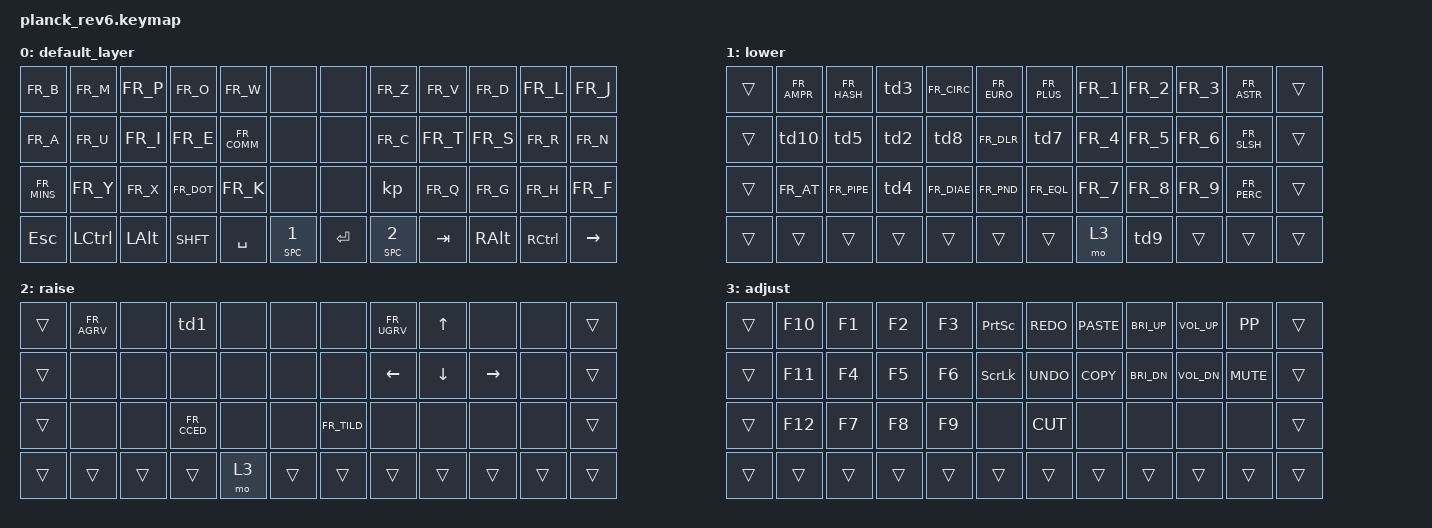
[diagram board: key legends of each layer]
/*
 * Copyright (c) 2020 The ZMK Contributors
 *
 * SPDX-License-Identifier: MIT
 */

#include "keys_fr.h"
#include <behaviors.dtsi>
#include <dt-bindings/zmk/keys.h>

/ {
    conditional_layers {
        compatible = "zmk,conditional-layers";

        tri_layer {
            if-layers = <4 6>;
            then-layer = <7>;
        };
    };

    combos {
        compatible = "zmk,combos";

        // symbols

        cb_excl {               // !
            bindings = <&kp EXCL>;
            key-positions = <1 13>;
            timeout-ms = <30>;
        };

        cb_at {               // @
            bindings = <&kp AT>;
            key-positions = <2 14>;
            timeout-ms = <30>;
        };

        cb_hash {               // #
            bindings = <&kp HASH>;
            key-positions = <3 15>;
            timeout-ms = <30>;
        };

        cb_dllr {               // $
            bindings = <&kp DLLR>;
            key-positions = <4 16>;
            timeout-ms = <30>;
        };

        cb_prcnt {              // %
            bindings = <&kp PRCNT>;
            key-positions = <5 17>;
            timeout-ms = <30>;
        };

        cb_caret {             // ^
            bindings = <&kp CARET>;
            key-positions = <6 18>;
            timeout-ms = <30>;
        };

        cb_amps {               // &
            bindings = <&kp AMPS>;
            key-positions = <7 19>;
            timeout-ms = <30>;
        };

        cb_mult {             // *
            bindings = <&kp ASTERISK>;
            key-positions = <8 20>;
            timeout-ms = <30>;
        };

        cb_lparen {
            bindings = <&kp LEFT_PARENTHESIS>;
            key-positions = <9 21>;
            timeout-ms = <30>;
        };

        cb_rparen {
            bindings = <&kp RIGHT_PARENTHESIS>;
            key-positions = <10 22>;
            timeout-ms = <30>;
        };
    };

    behaviors {
                lt_qk: layer_toggle_quick {
            compatible = "zmk,behavior-hold-tap";
            label = "LAYER_TOGGLE_QUICK";
            #binding-cells = <2>;
            flavor = "tap-preferred";
            tapping-term-ms = <150>;
            quick-tap-ms = <QUICK_TAP_MS>;
            bindings = <&mo>, <&kp>;
        };

        mt_sk: mod_tap_sticky {
            compatible = "zmk,behavior-hold-tap";
            label = "MOD_TAP_STICKY";
            #binding-cells = <2>;
            flavor = "tap-preferred";
            tapping-term-ms = <150>;
            quick-tap-ms = <200>;
            bindings = <&sk>, <&kp>;
        };

        ht: hold_tap {
            compatible = "zmk,behavior-hold-tap";
            label = "HOLD_TAP";
            #binding-cells = <2>;
            tapping_term_ms = <200>;
            quick_tap_ms = <200>;
            flavor = "tap-preferred";
            bindings = <&kp>, <&kp>;
        };

        lswp: left_swp {
            label = "LSWAP";
            compatible = "zmk,behavior-tap-dance";
            #binding-cells = <0>;
            tapping-term-ms = <200>;
            bindings = <&sk LGUI>, <&mo 0>, <&tog 0>;
        };

        rswp: right_swap {
            compatible = "zmk,behavior-tap-dance";
            label = "RIGHT_SWAP";
            #binding-cells = <0>;
            tapping-term-ms = <200>;   
            bindings = <&sk RGUI>, <&mo 0>, <&tog 0>;     
        };

        interrogation: interrogation {
            compatible = "zmk,behavior-mod-morph";
            label = "INTERROGATION";
            bindings = <&kp MINUS>, <&kp QUESTION>;

            #binding-cells = <0>;
            mods = <(MOD_LSFT|MOD_RSFT)>;
        };

        virgule: virgule {
            compatible = "zmk,behavior-mod-morph";
            label = "VIRGULE";
            bindings = <&kp COMMA>, <&kp SEMI>;

            #binding-cells = <0>;
            mods = <(MOD_LSFT|MOD_RSFT)>;
        };

        point: point {
            compatible = "zmk,behavior-mod-morph";
            label = "POINT";
            bindings = <&kp PERIOD>, <&kp COLON>;

            #binding-cells = <0>;
            mods = <(MOD_LSFT|MOD_RSFT)>;
        };

        zoom: zoom {
            compatible = "zmk,behavior-mod-morph";
            label = "ZOOM";
            bindings = <&kp LC(PLUS)>, <&kp LC(MINUS)>;

            #binding-cells = <0>;
            mods = <(MOD_LSFT|MOD_RSFT)>;        
        };

        circonflexe: circonflexe {
            compatible = "zmk,behavior-mod-morph";
            label = "CIRCONFLEXE";
            bindings = <&kp CARET>, <&kp RA(NUMBER_6)>;

            #binding-cells = <0>;
            mods = <(MOD_LSFT|MOD_RSFT)>;
        };

        inferieur: inferieur {
            compatible = "zmk,behavior-mod-morph";
            label = "INFERIEUR";
            bindings = <&kp LT>, <&none>;

            #binding-cells = <0>;
            mods = <(MOD_LSFT|MOD_RSFT)>;
        };

        superieur: superieur {
            compatible = "zmk,behavior-mod-morph";
            label = "SUPERIEUR";
            bindings = <&kp GREATER_THAN>, <&none>;

            #binding-cells = <0>;
            mods = <(MOD_LSFT|MOD_RSFT)>;
        };

        monnaies: monnaies {
            compatible = "zmk,behavior-mod-morph";
            label = "MONNAIES";
            bindings = <&kp DOLLAR>, <&sl 8>;

            #binding-cells = <0>;
            mods = <(MOD_LSFT|MOD_RSFT)>;
        };

        pourcent: pourcent {
            compatible = "zmk,behavior-mod-morph";
            label = "POURCENT";
            bindings = <&kp PERCENT>, <&none>;

            #binding-cells = <0>;
            mods = <(MOD_LSFT|MOD_RSFT)>;
        };

        anti_circonflexe: anti_circonflexe {
            compatible = "zmk,behavior-mod-morph";
            label = "ANTI_CIRCONFLEXE";
            bindings = <&kp LEFT_BRACE>, <&none>;
            #binding-cells = <0>;
            mods = <(MOD_LSFT|MOD_RSFT)>;
        };

        point_mort: point_mort {
            compatible = "zmk,behavior-mod-morph";
            label = "POINT_MORT";
            bindings = <&kp RIGHT_BRACE>, <&kp RA(N7)>;
            #binding-cells = <0>;
            mods = <(MOD_LSFT|MOD_RSFT)>;
        };

        egal: egal {
            compatible = "zmk,behavior-mod-morph";
            label = "EGAL";
            bindings = <&kp EQUAL>, <&none>;

            #binding-cells = <0>;
            mods = <(MOD_LSFT|MOD_RSFT)>;
        };

        tilde: tilde {
            compatible = "zmk,behavior-mod-morph";
            label = "TILDE";
            bindings = <&kp TILDE>, <&kp RA(TILDE)>;

            #binding-cells = <0>;
            mods = <(MOD_LSFT|MOD_RSFT)>;
        };

        onedk: onedk {
            compatible = "zmk,behavior-mod-morph";
            label = "ONEDK";
            bindings = <&sl 1>, <&kp EXCL>;

            #binding-cells = <0>;
            mods = <(MOD_LSFT|MOD_RSFT)>;
        };

        barre: barre {
            compatible = "zmk,behavior-mod-morph";
            label = "BARRE";
            bindings = <&kp MINUS>, <&kp RA(LS(N7))>;
            #binding-cells = <0>;
            mods = <(MOD_LSFT|MOD_RSFT)>;
        };

        grave: grave {
            compatible = "zmk,behavior-mod-morph";
            label = "GRAVE";
            bindings = <&kp GRAVE>, <&kp RA(GRAVE)>;

            #binding-cells = <0>;
            mods = <(MOD_LSFT|MOD_RSFT)>;
        };

        aigu: aigu {
            compatible = "zmk,behavior-mod-morph";
            label = "AIGU";
            bindings = <&kp SQT>, <&kp RA(SINGLE_QUOTE)>;

            #binding-cells = <0>;
            mods = <(MOD_LSFT|MOD_RSFT)>;
        };

        fois: fois {
            compatible = "zmk,behavior-mod-morph";
            label = "FOIS";
            bindings = <&kp ASTERISK>, <&kp RA(EQUAL)>;

            #binding-cells = <0>;
            mods = <(MOD_LSFT|MOD_RSFT)>;
        };


        division: division {
            compatible = "zmk,behavior-mod-morph";
            label = "DIVISION";
            bindings = <&kp SLASH>, <&kp RA(LS(EQUAL))>;

            #binding-cells = <0>;
            mods = <(MOD_LSFT|MOD_RSFT)>;
        };

        rond_mort: rond_mort {
            compatible = "zmk,behavior-mod-morph";
            label = "ROND_MORT";
            bindings = <&kp AT>, <&kp RA(N7)>;

            #binding-cells = <0>;
            mods = <(MOD_LSFT|MOD_RSFT)>;
        };

        barre_verticale: barre_verticale {
            compatible = "zmk,behavior-mod-morph";
            label = "BARRE_VERTICALE";
            bindings = <&kp LS(BACKSLASH)>, <&kp RA(LS(BACKSLASH))>;

            #binding-cells = <0>;
            mods = <(MOD_LSFT|MOD_RSFT)>;
        };

        truc: truc {
            compatible = "zmk,behavior-mod-morph";
            label = "TRUC";
            bindings = <&kp EXCLAMATION>, <&kp RA(BACKSLASH)>;

            #binding-cells = <0>;
            mods = <(MOD_LSFT|MOD_RSFT)>;
        };

        plus: plus {
            compatible = "zmk,behavior-mod-morph";
            label = "PLUS";
            bindings = <&kp PLUS>, <&none>;

            #binding-cells = <0>;
            mods = <(MOD_LSFT|MOD_RSFT)>;
        };

        backslash: backslash {
            compatible = "zmk,behavior-mod-morph";
            label = "BACKSLASH";
            bindings = <&kp BACKSLASH>, <&sl 5>;

            #binding-cells = <0>;
            mods = <(MOD_LSFT|MOD_RSFT)>;
        };
    };

    macros {
        e_circonflexe_min: e_circonflexe_min {
            compatible = "zmk,behavior-macro";
            #binding-cells = <0>;
            bindings =
                <&macro_press>,
                <&kp RALT>,
                <&macro_tap>,
                <&kp NUMBER_6>,
                <&macro_release>,
                <&kp RALT>,
                <&macro_tap>,
                <&kp E>;

            label = "E_CIRCONFLEXE_MIN";
        };

        e_circonflexe_maj: e_circonflexe_maj {
            compatible = "zmk,behavior-macro";
            #binding-cells = <0>;
            bindings =
                <&macro_press>,
                <&kp RALT>,
                <&macro_tap>,
                <&kp NUMBER_6>,
                <&macro_release>,
                <&kp RALT>,
                <&macro_tap>,
                <&kp LS(E)>;

            label = "E_CIRCONFLEXE_MAJ";
        };

        u_circonflexe_maj: u_circonflexe_maj {
            compatible = "zmk,behavior-macro";
            #binding-cells = <0>;
            bindings =
                <&macro_press>,
                <&kp RALT>,
                <&macro_tap>,
                <&kp NUMBER_6>,
                <&macro_release>,
                <&kp RALT>,
                <&macro_tap>,
                <&kp LS(U)>;

            label = "U_CIRCONFLEXE_MAJ";
        };

        u_circonflexe_min: u_circonflexe_min {
            compatible = "zmk,behavior-macro";
            #binding-cells = <0>;
            bindings =
                <&macro_press>,
                <&kp RALT>,
                <&macro_tap>,
                <&kp NUMBER_6>,
                <&macro_release>,
                <&kp RALT>,
                <&macro_tap>,
                <&kp U>;

            label = "U_CIRCONFLEXE_MIN";
        };

        i_circonflexe_min: i_circonflexe_min {
            compatible = "zmk,behavior-macro";
            #binding-cells = <0>;
            bindings =
                <&macro_press>,
                <&kp RALT>,
                <&macro_tap>,
                <&kp NUMBER_6>,
                <&macro_release>,
                <&kp RALT>,
                <&macro_tap>,
                <&kp I>;

            label = "I_CIRCONFLEXE_MIN";
        };

        i_circonflexe_maj: i_circonflexe_maj {
            compatible = "zmk,behavior-macro";
            #binding-cells = <0>;
            bindings =
                <&macro_press>,
                <&kp RALT>,
                <&macro_tap>,
                <&kp NUMBER_6>,
                <&macro_release>,
                <&kp RALT>,
                <&macro_tap>,
                <&kp LS(I)>;

            label = "I_CIRCONFLEXE_MAJ";
        };

        a_circonflexe_maj: a_circonflexe_maj {
            compatible = "zmk,behavior-macro";
            #binding-cells = <0>;
            bindings =
                <&macro_press>,
                <&kp RALT>,
                <&macro_tap>,
                <&kp NUMBER_6>,
                <&macro_release>,
                <&kp RALT>,
                <&macro_tap>,
                <&kp LS(A)>;

            label = "A_CIRCONFLEXE_MAJ";
        };

        a_circonflexe_min: a_circonflexe_min {
            compatible = "zmk,behavior-macro";
            #binding-cells = <0>;
            bindings =
                <&macro_press>,
                <&kp RALT>,
                <&macro_tap>,
                <&kp NUMBER_6>,
                <&macro_release>,
                <&kp RALT>,
                <&macro_tap>,
                <&kp A>;

            label = "A_CIRCONFLEXE_MIN";
        };

        o_circonflexe_min: o_circonflexe_min {
            compatible = "zmk,behavior-macro";
            #binding-cells = <0>;
            bindings =
                <&macro_press>,
                <&kp RALT>,
                <&macro_tap>,
                <&kp NUMBER_6>,
                <&macro_release>,
                <&kp RALT>,
                <&macro_tap>,
                <&kp O>;

            label = "O_CIRCONFLEXE_MIN";
        };

        o_circonflexe_maj: o_circonflexe_maj {
            compatible = "zmk,behavior-macro";
            #binding-cells = <0>;
            bindings =
                <&macro_press>,
                <&kp RALT>,
                <&macro_tap>,
                <&kp NUMBER_6>,
                <&macro_release>,
                <&kp RALT>,
                <&macro_tap>,
                <&kp LS(O)>;

            label = "O_CIRCONFLEXE_MAJ";
        };
    };
        
    keymap {
        compatible = "zmk,keymap";

        default_layer {
            // -----------------------------------------------------------------------------------------
            // |  TAB  |  Q   |  W   |  E   |  R   |  T   |   Y   |  U    |  I   |  O   |   P   | BSPC  |
            // |  ESC  |  A   |  S   |  D   |  F   |  G   |   H   |  J    |  K   |  L   |   ;   |  '    |
            // | SHIFT |  Z   |  X   |  C   |  V   |  B   |   N   |  M    |  ,   |  .   |   /   |  RET  |
            // |       | LCTL | LALT | LGUI | LOWR |     SPACE    |  RAIS | LARW | DARW | UARW  |  RARW |
            bindings = <
                &kp FR_B        &kp FR_M        &kp FR_P        &kp FR_O        &kp FR_W        &none           &none           &kp FR_Z        &kp FR_V        &kp FR_D        &kp FR_L        &kp FR_J
                &kp FR_A        &kp FR_U        &kp FR_I        &kp FR_E        &kp FR_COMM     &none           &none           &kp FR_C        &kp FR_T        &kp FR_S        &kp FR_R        &kp FR_N
                &kp FR_MINS     &kp FR_Y        &kp FR_X        &kp FR_DOT      &kp FR_K        &none           &none           &kp      &kp FR_Q        &kp FR_G        &kp FR_H        &kp FR_F
                &kp ESC         &kp LCTL        &kp LALT        &kp SHFT        &kp SPACE       &lt SPC 1       &kp RET         &lt SPC 2       &kp TAB         &kp RALT        &kp RCTL        &kp RIGHT
            >;
        };

        lower {
            bindings = <
                &trans          &kp FR_AMPR     &kp FR_HASH     &td3            &kp FR_CIRC     &kp FR_EURO     &kp FR_PLUS     &kp FR_1        &kp FR_2       &kp FR_3        &kp FR_ASTR     &trans
                &trans          &td10           &td5            &td2            &td8            &kp FR_DLR      &td7            &kp FR_4        &kp FR_5        &kp FR_6        &kp FR_SLSH     &trans
                &trans          &kp FR_AT       &kp FR_PIPE     &td4            &kp FR_DIAE     &kp FR_PND      &kp FR_EQL      &kp FR_7        &kp FR_8        &kp FR_9        &kp FR_PERC     &trans
                &trans          &trans          &trans          &trans          &trans          &trans          &trans          &mo 3           &td9            &trans          &trans          &trans
            >;
        };

        raise {
            bindings = <
                &trans          &kp FR_AGRV     &none           &td1            &none           &none           &none           &kp FR_UGRV     &kp UP          &none           &none           &trans
                &trans          &none           &none           &none           &none           &none           &none           &kp LEFT        &kp DOWN        &kp RIGHT       &none           &trans
                &trans          &none           &none           &kp FR_CCED     &none           &none           &kp FR_TILD     &none           &none           &none           &none           &trans
                &trans          &trans          &trans          &trans          &mo 3           &trans          &trans          &trans          &trans          &trans          &trans          &trans
            >;
        };
        adjust {
            bindings = <
                &trans          &kp F10         &kp F1          &kp F2          &kp F3          &kp PSCRN       &kp K_REDO      &kp K_PASTE     &kp C_BRI_UP    &kp K_VOL_UP    &kp K_PP        &trans
                &trans          &kp F11         &kp F4          &kp F5          &kp F6          &kp SLCK        &kp K_UNDO      &kp K_COPY      &kp C_BRI_DN    &kp K_VOL_DN    &kp K_MUTE      &trans
                &trans          &kp F12         &kp F7          &kp F8          &kp F9          &none           &kp K_CUT       &none           &none           &none           &none           &trans
                &trans          &trans          &trans          &trans          &trans          &trans          &trans          &trans          &trans          &trans          &trans          &trans
            >;
        };
    };
};
